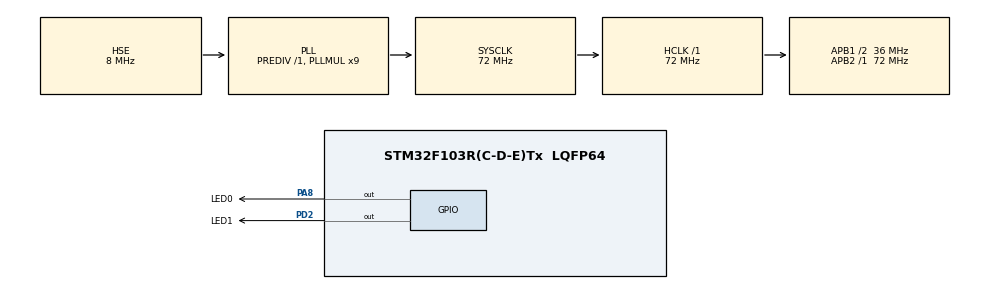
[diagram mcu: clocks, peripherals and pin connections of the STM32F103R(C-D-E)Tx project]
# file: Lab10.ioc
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FREERTOS.Tasks01=Task_LED1,0,128,Func_LED1,Default,NULL,Dynamic,NULL,NULL;Task_LED0,0,128,Func_LED0,Default,NULL,Dynamic,NULL,NULL
FREERTOS.configUSE_NEWLIB_REENTRANT=1
Mcu.Family=STM32F1
Mcu.Name=STM32F103R(C-D-E)Tx
Mcu.Package=LQFP64
NVIC.PriorityGroup=NVIC_PRIORITYGROUP_4
NVIC.TIM3_IRQn=true\:15\:0\:false\:false\:true\:false\:false\:true
NVIC.TimeBase=TIM3_IRQn
NVIC.TimeBaseIP=TIM3
PA13.Mode=Serial_Wire
PA13.Signal=SYS_JTMS-SWDIO
PA14.Mode=Serial_Wire
PA14.Signal=SYS_JTCK-SWCLK
PA8.GPIO_Label=LED0
PA8.Signal=GPIO_Output
PD0-OSC_IN.Mode=HSE-External-Oscillator
PD0-OSC_IN.Signal=RCC_OSC_IN
PD1-OSC_OUT.Mode=HSE-External-Oscillator
PD1-OSC_OUT.Signal=RCC_OSC_OUT
PD2.GPIO_Label=LED1
PD2.Signal=GPIO_Output
ProjectManager.HeapSize=0x200
ProjectManager.StackSize=0x400
ProjectManager.TargetToolchain=STM32CubeIDE
RCC.AHBFreq_Value=72000000
RCC.APB1CLKDivider=RCC_HCLK_DIV2
RCC.APB1Freq_Value=36000000
RCC.APB1TimFreq_Value=72000000
RCC.APB2Freq_Value=72000000
RCC.APB2TimFreq_Value=72000000
RCC.HCLKFreq_Value=72000000
RCC.PLLMUL=RCC_PLL_MUL9
RCC.PLLSourceVirtual=RCC_PLLSOURCE_HSE
RCC.SYSCLKFreq_VALUE=72000000
RCC.SYSCLKSource=RCC_SYSCLKSOURCE_PLLCLK
RCC.USBFreq_Value=72000000
VP_FREERTOS_VS_CMSIS_V1.Mode=CMSIS_V1
VP_SYS_VS_tim3.Mode=TIM3
board=custom

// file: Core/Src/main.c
/* USER CODE BEGIN Header */
/**
  ******************************************************************************
  * @file           : main.c
  * @brief          : Main program body
  ******************************************************************************
  * @attention
  *
  * <h2><center>&copy; Copyright (c) 2021 STMicroelectronics.
  * All rights reserved.</center></h2>
  *
  * This software component is licensed by ST under BSD 3-Clause license,
  * the "License"; You may not use this file except in compliance with the
  * License. You may obtain a copy of the License at:
  *                        opensource.org/licenses/BSD-3-Clause
  *
  ******************************************************************************
  */
/* USER CODE END Header */
#include "main.h"
#include "cmsis_os.h"
#include "gpio.h"

void SystemClock_Config(void);
void MX_FREERTOS_Init(void);

int main(void)
{

  /* MCU Configuration--------------------------------------------------------*/

  /* Reset of all peripherals, Initializes the Flash interface and the Systick. */
  HAL_Init();

  /* Configure the system clock */
  SystemClock_Config();

  /* Initialize all configured peripherals */
  MX_GPIO_Init();

  /* Call init function for freertos objects (in freertos.c) */
  MX_FREERTOS_Init();
  /* Start scheduler */
  osKernelStart();

  /* We should never get here as control is now taken by the scheduler */
  /* Infinite loop */
  while (1)
  {

  }
}

void SystemClock_Config(void)
{
  RCC_OscInitTypeDef RCC_OscInitStruct = {0};
  RCC_ClkInitTypeDef RCC_ClkInitStruct = {0};

  /** Initializes the RCC Oscillators according to the specified parameters
  * in the RCC_OscInitTypeDef structure.
  */
  RCC_OscInitStruct.OscillatorType = RCC_OSCILLATORTYPE_HSE;
  RCC_OscInitStruct.HSEState = RCC_HSE_ON;
  RCC_OscInitStruct.HSEPredivValue = RCC_HSE_PREDIV_DIV1;
  RCC_OscInitStruct.HSIState = RCC_HSI_ON;
  RCC_OscInitStruct.PLL.PLLState = RCC_PLL_ON;
  RCC_OscInitStruct.PLL.PLLSource = RCC_PLLSOURCE_HSE;
  RCC_OscInitStruct.PLL.PLLMUL = RCC_PLL_MUL9;
  if (HAL_RCC_OscConfig(&RCC_OscInitStruct) != HAL_OK)
  {
    Error_Handler();
  }
  /** Initializes the CPU, AHB and APB buses clocks
  */
  RCC_ClkInitStruct.ClockType = RCC_CLOCKTYPE_HCLK|RCC_CLOCKTYPE_SYSCLK
                              |RCC_CLOCKTYPE_PCLK1|RCC_CLOCKTYPE_PCLK2;
  RCC_ClkInitStruct.SYSCLKSource = RCC_SYSCLKSOURCE_PLLCLK;
  RCC_ClkInitStruct.AHBCLKDivider = RCC_SYSCLK_DIV1;
  RCC_ClkInitStruct.APB1CLKDivider = RCC_HCLK_DIV2;
  RCC_ClkInitStruct.APB2CLKDivider = RCC_HCLK_DIV1;

  if (HAL_RCC_ClockConfig(&RCC_ClkInitStruct, FLASH_LATENCY_2) != HAL_OK)
  {
    Error_Handler();
  }
}

void HAL_TIM_PeriodElapsedCallback(TIM_HandleTypeDef *htim)
{
  if (htim->Instance == TIM3) {
    HAL_IncTick();
  }
}

void Error_Handler(void)
{
  __disable_irq();
  while (1)
  {
  }
}

/************************ (C) COPYRIGHT STMicroelectronics *****END OF FILE****/

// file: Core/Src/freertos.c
/* USER CODE BEGIN Header */
/**
  ******************************************************************************
  * File Name          : freertos.c
  * Description        : Code for freertos applications
  ******************************************************************************
  * @attention
  *
  * <h2><center>&copy; Copyright (c) 2021 STMicroelectronics.
  * All rights reserved.</center></h2>
  *
  * This software component is licensed by ST under Ultimate Liberty license
  * SLA0044, the "License"; You may not use this file except in compliance with
  * the License. You may obtain a copy of the License at:
  *                             www.st.com/SLA0044
  *
  ******************************************************************************
  */
/* USER CODE END Header */

#include "FreeRTOS.h"
#include "task.h"
#include "main.h"
#include "cmsis_os.h"

osThreadId Task_LED1Handle;
osThreadId Task_LED0Handle;

void Func_LED1(void const * argument);
void Func_LED0(void const * argument);

void MX_FREERTOS_Init(void); /* (MISRA C 2004 rule 8.1) */

/* GetIdleTaskMemory prototype (linked to static allocation support) */
void vApplicationGetIdleTaskMemory( StaticTask_t **ppxIdleTaskTCBBuffer, StackType_t **ppxIdleTaskStackBuffer, uint32_t *pulIdleTaskStackSize );

/* USER CODE BEGIN GET_IDLE_TASK_MEMORY */
static StaticTask_t xIdleTaskTCBBuffer;
static StackType_t xIdleStack[configMINIMAL_STACK_SIZE];

void vApplicationGetIdleTaskMemory( StaticTask_t **ppxIdleTaskTCBBuffer, StackType_t **ppxIdleTaskStackBuffer, uint32_t *pulIdleTaskStackSize )
{
  *ppxIdleTaskTCBBuffer = &xIdleTaskTCBBuffer;
  *ppxIdleTaskStackBuffer = &xIdleStack[0];
  *pulIdleTaskStackSize = configMINIMAL_STACK_SIZE;
  /* place for user code */
}
/* USER CODE END GET_IDLE_TASK_MEMORY */

void MX_FREERTOS_Init(void) {

  /* Create the thread(s) */
  /* definition and creation of Task_LED1 */
  osThreadDef(Task_LED1, Func_LED1, osPriorityNormal, 0, 128);
  Task_LED1Handle = osThreadCreate(osThread(Task_LED1), NULL);

  /* definition and creation of Task_LED0 */
  osThreadDef(Task_LED0, Func_LED0, osPriorityNormal, 0, 128);
  Task_LED0Handle = osThreadCreate(osThread(Task_LED0), NULL);

}

void Func_LED1(void const * argument)
{
  /* USER CODE BEGIN Func_LED1 */
  /* Infinite loop */
  for(;;)
  {
	HAL_GPIO_TogglePin(LED1_GPIO_Port, LED1_Pin);
    osDelay(500);
  }
  /* USER CODE END Func_LED1 */
}

void Func_LED0(void const * argument)
{
  /* USER CODE BEGIN Func_LED0 */
  /* Infinite loop */
  for(;;)
  {
	HAL_GPIO_TogglePin(LED0_GPIO_Port, LED0_Pin);
    osDelay(500);
  }
  /* USER CODE END Func_LED0 */
}

/************************ (C) COPYRIGHT STMicroelectronics *****END OF FILE****/
